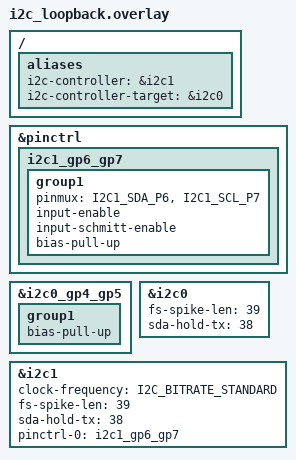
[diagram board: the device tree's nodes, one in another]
/* SPDX-License-Identifier: Apache-2.0 OR MIT */
/*
 * samples/drivers/i2c/rtio_loopback: I2C1 (GP6 SDA, GP7 SCL) as the
 * controller and I2C0 (GP4 SDA, GP5 SCL, i2c0.overlay) as the target, at
 * the standard rate. The harness joins SDA to SDA and SCL to SCL with
 * open-drain jumpers, as the sample's i2c_bus_short fixture does. Both
 * buses take the pads' pull-ups, as pico-examples' slave_mem_i2c does on
 * the same pins (gpio_pull_up); without them the controller's first
 * transfer fails on the carrier. Both take the spike filter and
 * SDA hold pico-sdk gives a 100 kHz bus (hardware_i2c/i2c.c: spklen =
 * lcnt / 16, 39 cycles on the Pico 1, 260-310 ns; 38 cycles, 300 ns, of
 * hold); the rpi_pico boards leave the DesignWare defaults, one cycle each.
 * The clock jumper's handover shows SCL high for two of its harness's PIO
 * cycles and a synchroniser, which a shorter filter passes on as a clock
 * on a 125 MHz RP2040 harness.
 */
#include <zephyr/dt-bindings/i2c/i2c.h>

/ {
	aliases {
		i2c-controller = &i2c1;
		i2c-controller-target = &i2c0;
	};
};

&pinctrl {
	i2c1_gp6_gp7: i2c1_gp6_gp7 {
		group1 {
			pinmux = <I2C1_SDA_P6>, <I2C1_SCL_P7>;
			input-enable;
			input-schmitt-enable;
			bias-pull-up;
		};
	};
};

&i2c0_gp4_gp5 {
	group1 {
		bias-pull-up;
	};
};

&i2c0 {
	fs-spike-len = <39>;
	sda-hold-tx = <38>;
};

&i2c1 {
	status = "okay";
	clock-frequency = <I2C_BITRATE_STANDARD>;
	fs-spike-len = <39>;
	sda-hold-tx = <38>;
	pinctrl-0 = <&i2c1_gp6_gp7>;
	pinctrl-names = "default";
};
